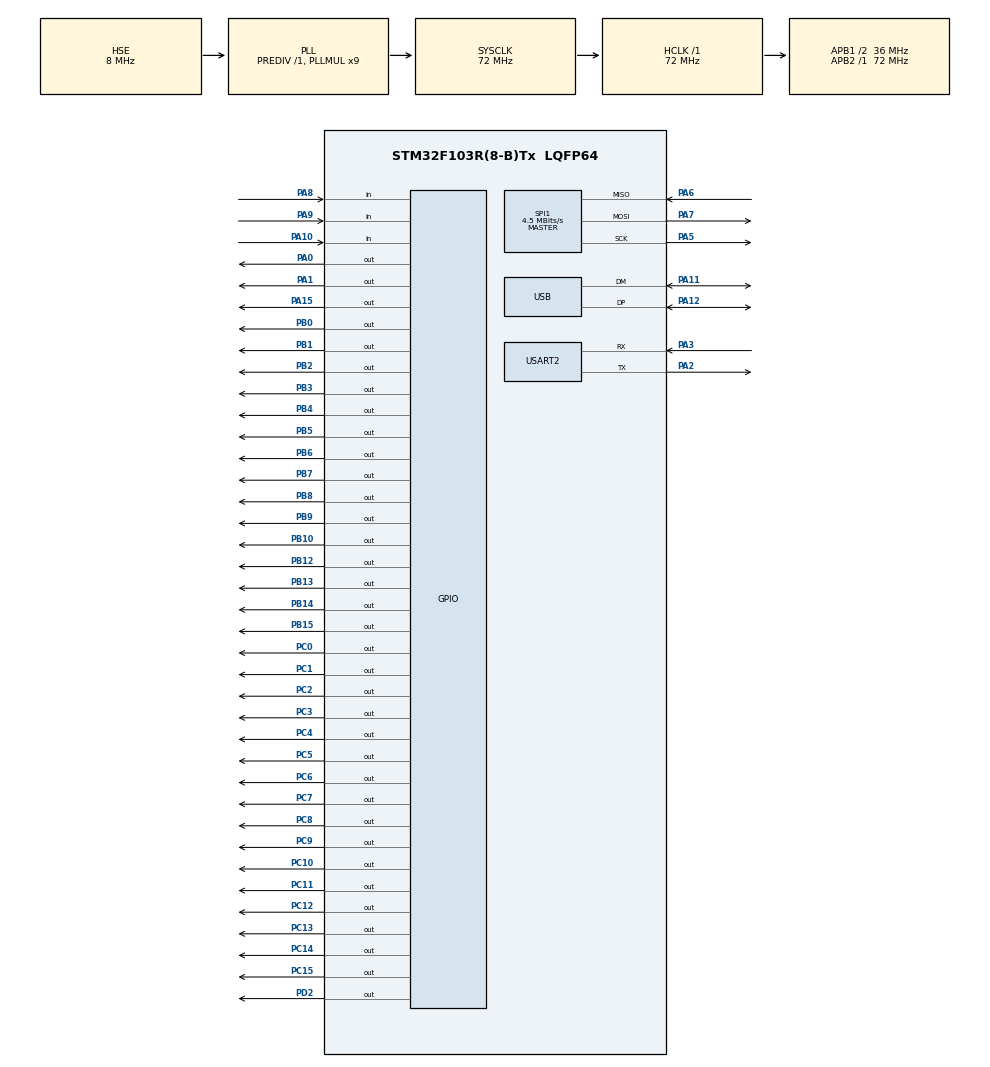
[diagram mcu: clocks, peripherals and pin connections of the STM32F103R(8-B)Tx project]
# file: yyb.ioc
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FREERTOS.Tasks01=defaultTask,0,128,StartDefaultTask,Default
Mcu.Family=STM32F1
Mcu.Name=STM32F103R(8-B)Tx
Mcu.Package=LQFP64
NVIC.PriorityGroup=NVIC_PRIORITYGROUP_4
NVIC.TIM2_IRQn=true\:0\:0\:false\:false\:true\:false
NVIC.TimeBase=TIM2_IRQn
NVIC.TimeBaseIP=TIM2
NVIC.USB_LP_CAN1_RX0_IRQn=true\:5\:0\:false\:false\:true\:true
PA0-WKUP.Signal=GPIO_Output
PA1.Signal=GPIO_Output
PA10.Signal=GPIO_Input
PA11.Mode=Device
PA11.Signal=USB_DM
PA12.Mode=Device
PA12.Signal=USB_DP
PA13.Mode=Serial_Wire
PA13.Signal=SYS_JTMS-SWDIO
PA14.Mode=Serial_Wire
PA14.Signal=SYS_JTCK-SWCLK
PA15.Signal=GPIO_Output
PA2.Mode=Asynchronous
PA2.Signal=USART2_TX
PA3.Mode=Asynchronous
PA3.Signal=USART2_RX
PA5.Mode=Full_Duplex_Master
PA5.Signal=SPI1_SCK
PA6.Mode=Full_Duplex_Master
PA6.Signal=SPI1_MISO
PA7.Mode=Full_Duplex_Master
PA7.Signal=SPI1_MOSI
PA8.Signal=GPIO_Input
PA9.Signal=GPIO_Input
PB0.Signal=GPIO_Output
PB1.Signal=GPIO_Output
PB10.Signal=GPIO_Output
PB12.Signal=GPIO_Output
PB13.Signal=GPIO_Output
PB14.Signal=GPIO_Output
PB15.Signal=GPIO_Output
PB2.Signal=GPIO_Output
PB3.Signal=GPIO_Output
PB4.Signal=GPIO_Output
PB5.Signal=GPIO_Output
PB6.Signal=GPIO_Output
PB7.Signal=GPIO_Output
PB8.Signal=GPIO_Output
PB9.Signal=GPIO_Output
PC0.Signal=GPIO_Output
PC1.Signal=GPIO_Output
PC10.Signal=GPIO_Output
PC11.Signal=GPIO_Output
PC12.Signal=GPIO_Output
PC13-TAMPER-RTC.Signal=GPIO_Output
PC14-OSC32_IN.Signal=GPIO_Output
PC15-OSC32_OUT.Signal=GPIO_Output
PC2.Signal=GPIO_Output
PC3.Signal=GPIO_Output
PC4.Signal=GPIO_Output
PC5.Signal=GPIO_Output
PC6.Signal=GPIO_Output
PC7.Signal=GPIO_Output
PC8.Signal=GPIO_Output
PC9.Signal=GPIO_Output
PD0-OSC_IN.Mode=HSE-External-Oscillator
PD0-OSC_IN.Signal=RCC_OSC_IN
PD1-OSC_OUT.Mode=HSE-External-Oscillator
PD1-OSC_OUT.Signal=RCC_OSC_OUT
PD2.Signal=GPIO_Output
ProjectManager.HeapSize=0x200
ProjectManager.StackSize=0x400
ProjectManager.TargetToolchain=EWARM
RCC.AHBFreq_Value=72000000
RCC.APB1CLKDivider=RCC_HCLK_DIV2
RCC.APB1Freq_Value=36000000
RCC.APB1TimFreq_Value=72000000
RCC.APB2Freq_Value=72000000
RCC.APB2TimFreq_Value=72000000
RCC.HCLKFreq_Value=72000000
RCC.HSIState=RCC_HSI_ON
RCC.PLLMUL=RCC_PLL_MUL9
RCC.SYSCLKFreq_VALUE=72000000
RCC.SYSCLKSource=RCC_SYSCLKSOURCE_PLLCLK
RCC.USBFreq_Value=48000000
RCC.USBPrescaler=RCC_USBCLKSOURCE_PLL_DIV1_5
SPI1.BaudRatePrescaler=SPI_BAUDRATEPRESCALER_16
SPI1.CalculateBaudRate=4.5 MBits/s
SPI1.Mode=SPI_MODE_MASTER
USB_DEVICE.USBD_HandleTypeDef=hUsbDeviceFS
USB_DEVICE.VirtualMode=Hid
USB_DEVICE.VirtualModeFS=Hid_FS
VP_FREERTOS_VS_ENABLE.Mode=Enabled
VP_SYS_VS_tim2.Mode=TIM2
VP_USB_DEVICE_VS_USB_DEVICE_HID_FS.Mode=HID_FS
board=yyb

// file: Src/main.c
/**
  ******************************************************************************
  * File Name          : main.c
  * Description        : Main program body
  ******************************************************************************
  *
  * Copyright (c) 2017 STMicroelectronics International N.V.
  * All rights reserved.
  *
  * Redistribution and use in source and binary forms, with or without
  * modification, are permitted, provided that the following conditions are met:
  *
  * 1. Redistribution of source code must retain the above copyright notice,
  *    this list of conditions and the following disclaimer.
  * 2. Redistributions in binary form must reproduce the above copyright notice,
  *    this list of conditions and the following disclaimer in the documentation
  *    and/or other materials provided with the distribution.
  * 3. Neither the name of STMicroelectronics nor the names of other
  *    contributors to this software may be used to endorse or promote products
  *    derived from this software without specific written permission.
  * 4. This software, including modifications and/or derivative works of this
  *    software, must execute solely and exclusively on microcontroller or
  *    microprocessor devices manufactured by or for STMicroelectronics.
  * 5. Redistribution and use of this software other than as permitted under
  *    this license is void and will automatically terminate your rights under
  *    this license.
  *
  * THIS SOFTWARE IS PROVIDED BY STMICROELECTRONICS AND CONTRIBUTORS "AS IS"
  * AND ANY EXPRESS, IMPLIED OR STATUTORY WARRANTIES, INCLUDING, BUT NOT
  * LIMITED TO, THE IMPLIED WARRANTIES OF MERCHANTABILITY, FITNESS FOR A
  * PARTICULAR PURPOSE AND NON-INFRINGEMENT OF THIRD PARTY INTELLECTUAL PROPERTY
  * RIGHTS ARE DISCLAIMED TO THE FULLEST EXTENT PERMITTED BY LAW. IN NO EVENT
  * SHALL STMICROELECTRONICS OR CONTRIBUTORS BE LIABLE FOR ANY DIRECT, INDIRECT,
  * INCIDENTAL, SPECIAL, EXEMPLARY, OR CONSEQUENTIAL DAMAGES (INCLUDING, BUT NOT
  * LIMITED TO, PROCUREMENT OF SUBSTITUTE GOODS OR SERVICES; LOSS OF USE, DATA,
  * OR PROFITS; OR BUSINESS INTERRUPTION) HOWEVER CAUSED AND ON ANY THEORY OF
  * LIABILITY, WHETHER IN CONTRACT, STRICT LIABILITY, OR TORT (INCLUDING
  * NEGLIGENCE OR OTHERWISE) ARISING IN ANY WAY OUT OF THE USE OF THIS SOFTWARE,
  * EVEN IF ADVISED OF THE POSSIBILITY OF SUCH DAMAGE.
  *
  ******************************************************************************
  */
#include "main.h"
#include "stm32f1xx_hal.h"
#include "cmsis_os.h"
#include "usb_device.h"
#include "display.h"
#include "gpio.h"
#include "sensor_task.h"
#include "command.h"

SPI_HandleTypeDef hspi1;

UART_HandleTypeDef huart2;

osThreadId defaultTaskHandle;

/* USER CODE BEGIN PV */
/* Private variables ---------------------------------------------------------*/

/* USER CODE END PV */

void SystemClock_Config(void);
void Error_Handler(void);
/* static void MX_GPIO_Init(void); */
static void MX_SPI1_Init(void);
static void MX_USART2_UART_Init(void);
void StartDefaultTask(void const * argument);

/* USER CODE BEGIN PFP */
/* Private function prototypes -----------------------------------------------*/

/* USER CODE END PFP */

int main(void)
{

  /* MCU Configuration----------------------------------------------------------*/

  /* Reset of all peripherals, Initializes the Flash interface and the Systick. */
  HAL_Init();

  /* Configure the system clock */
  SystemClock_Config();

  /* Initialize all configured peripherals */
  gpio_init();
  MX_SPI1_Init();
  MX_USART2_UART_Init();

  /* USER CODE BEGIN 2 */
  display_init();
  sensorTaskInit();
  cmd_init();
  /* USER CODE END 2 */

  /* Create the thread(s) */
  /* definition and creation of defaultTask */
  osThreadDef(defaultTask, StartDefaultTask, osPriorityNormal, 0, 128);
  defaultTaskHandle = osThreadCreate(osThread(defaultTask), NULL);

  /* Start scheduler */
  osKernelStart();

  /* We should never get here as control is now taken by the scheduler */

  /* Infinite loop */
  while (1)
  {

  }

}

/** System Clock Configuration
*/
void SystemClock_Config(void)
{

  RCC_OscInitTypeDef RCC_OscInitStruct;
  RCC_ClkInitTypeDef RCC_ClkInitStruct;
  RCC_PeriphCLKInitTypeDef PeriphClkInit;

    /**Initializes the CPU, AHB and APB busses clocks
    */
  RCC_OscInitStruct.OscillatorType = RCC_OSCILLATORTYPE_HSE;
  RCC_OscInitStruct.HSEState = RCC_HSE_ON;
  RCC_OscInitStruct.HSEPredivValue = RCC_HSE_PREDIV_DIV1;
  RCC_OscInitStruct.HSIState = RCC_HSI_ON;
  RCC_OscInitStruct.PLL.PLLState = RCC_PLL_ON;
  RCC_OscInitStruct.PLL.PLLSource = RCC_PLLSOURCE_HSE;
  RCC_OscInitStruct.PLL.PLLMUL = RCC_PLL_MUL9;
  if (HAL_RCC_OscConfig(&RCC_OscInitStruct) != HAL_OK)
  {
    Error_Handler();
  }

    /**Initializes the CPU, AHB and APB busses clocks
    */
  RCC_ClkInitStruct.ClockType = RCC_CLOCKTYPE_HCLK|RCC_CLOCKTYPE_SYSCLK
                              |RCC_CLOCKTYPE_PCLK1|RCC_CLOCKTYPE_PCLK2;
  RCC_ClkInitStruct.SYSCLKSource = RCC_SYSCLKSOURCE_PLLCLK;
  RCC_ClkInitStruct.AHBCLKDivider = RCC_SYSCLK_DIV1;
  RCC_ClkInitStruct.APB1CLKDivider = RCC_HCLK_DIV2;
  RCC_ClkInitStruct.APB2CLKDivider = RCC_HCLK_DIV1;

  if (HAL_RCC_ClockConfig(&RCC_ClkInitStruct, FLASH_LATENCY_2) != HAL_OK)
  {
    Error_Handler();
  }

  PeriphClkInit.PeriphClockSelection = RCC_PERIPHCLK_USB;
  PeriphClkInit.UsbClockSelection = RCC_USBCLKSOURCE_PLL_DIV1_5;
  if (HAL_RCCEx_PeriphCLKConfig(&PeriphClkInit) != HAL_OK)
  {
    Error_Handler();
  }

    /**Configure the Systick interrupt time
    */
  HAL_SYSTICK_Config(HAL_RCC_GetHCLKFreq()/1000);

    /**Configure the Systick
    */
  HAL_SYSTICK_CLKSourceConfig(SYSTICK_CLKSOURCE_HCLK);

  /* SysTick_IRQn interrupt configuration */
  HAL_NVIC_SetPriority(SysTick_IRQn, 15, 0);
}

/* SPI1 init function */
static void MX_SPI1_Init(void)
{
  GPIO_InitTypeDef GPIO_InitStruct;
  HAL_GPIO_WritePin(GPIO_PORT_BMI160_CS, GPIO_PIN_BMI160_CS, GPIO_PIN_SET);
  GPIO_InitStruct.Pin = GPIO_PIN_BMI160_CS;
  GPIO_InitStruct.Mode = GPIO_MODE_OUTPUT_PP;
  GPIO_InitStruct.Pull = GPIO_NOPULL;
  GPIO_InitStruct.Speed = GPIO_SPEED_FREQ_LOW;
  HAL_GPIO_Init(GPIO_PORT_BMI160_CS, &GPIO_InitStruct);

  hspi1.Instance = SPI1;
  hspi1.Init.Mode = SPI_MODE_MASTER;
  hspi1.Init.Direction = SPI_DIRECTION_2LINES;
  hspi1.Init.DataSize = SPI_DATASIZE_8BIT;
  hspi1.Init.CLKPolarity = SPI_POLARITY_HIGH;
  hspi1.Init.CLKPhase = SPI_PHASE_2EDGE;
  hspi1.Init.NSS = SPI_NSS_SOFT;
  hspi1.Init.BaudRatePrescaler = SPI_BAUDRATEPRESCALER_16;
  hspi1.Init.FirstBit = SPI_FIRSTBIT_MSB;
  hspi1.Init.TIMode = SPI_TIMODE_DISABLE;
  hspi1.Init.CRCCalculation = SPI_CRCCALCULATION_DISABLE;
  hspi1.Init.CRCPolynomial = 10;
  if (HAL_SPI_Init(&hspi1) != HAL_OK)
  {
    Error_Handler();
  }
}

/* USART2 init function */
static void MX_USART2_UART_Init(void)
{

  huart2.Instance = USART2;
  huart2.Init.BaudRate = 115200;
  huart2.Init.WordLength = UART_WORDLENGTH_8B;
  huart2.Init.StopBits = UART_STOPBITS_1;
  huart2.Init.Parity = UART_PARITY_NONE;
  huart2.Init.Mode = UART_MODE_TX_RX;
  huart2.Init.HwFlowCtl = UART_HWCONTROL_NONE;
  huart2.Init.OverSampling = UART_OVERSAMPLING_16;
  if (HAL_UART_Init(&huart2) != HAL_OK)
  {
    Error_Handler();
  }

}

/* StartDefaultTask function */
void StartDefaultTask(void const * argument)
{
  /* init code for USB_DEVICE */
  MX_USB_DEVICE_Init();

  for(;;)
  {
    osDelay(1);
  }
}

void HAL_TIM_PeriodElapsedCallback(TIM_HandleTypeDef *htim)
{
  if (htim->Instance == TIM2) {
    HAL_IncTick();
  }
}

void Error_Handler(void)
{
  while(1)
  {
  }
}

/************************ (C) COPYRIGHT STMicroelectronics *****END OF FILE****/
